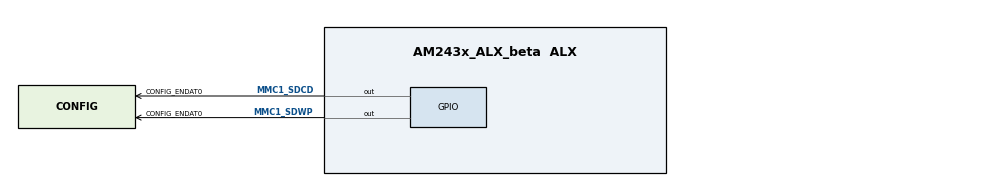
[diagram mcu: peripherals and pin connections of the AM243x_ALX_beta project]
/**
 * @cliArgs --device "AM243x_ALX_beta" --package "ALX" --part "ALX" --context "r5fss0-0" --product "MOTOR_CONTROL_SDK@09.01.00"
 * @versions {"tool":"1.18.0+3266"}
 */

/**
 * Import the modules used in this configuration.
 */
const debug_log  = scripting.addModule("/kernel/dpl/debug_log");
const mpu_armv7  = scripting.addModule("/kernel/dpl/mpu_armv7", {}, false);
const mpu_armv71 = mpu_armv7.addInstance();
const mpu_armv72 = mpu_armv7.addInstance();
const mpu_armv73 = mpu_armv7.addInstance();
const mpu_armv74 = mpu_armv7.addInstance();
const mpu_armv75 = mpu_armv7.addInstance();
const timer      = scripting.addModule("/kernel/dpl/timer", {}, false);
const timer1     = timer.addInstance();
const endat      = scripting.addModule("/position_sense/endat", {}, false);
const endat1     = endat.addInstance();

/**
 * Write custom configuration values to the imported modules.
 */
debug_log.enableUartLog        = true;
debug_log.enableCssLog         = false;
debug_log.uartLog.$name        = "CONFIG_UART_CONSOLE";
debug_log.uartLog.UART.$assign = "USART0";

const uart_v0_template  = scripting.addModule("/drivers/uart/v0/uart_v0_template", {}, false);
const uart_v0_template1 = uart_v0_template.addInstance({}, false);
uart_v0_template1.$name = "drivers_uart_v0_uart_v0_template0";
debug_log.uartLog.child = uart_v0_template1;

mpu_armv71.$name             = "CONFIG_MPU_REGION0";
mpu_armv71.size              = 31;
mpu_armv71.attributes        = "Device";
mpu_armv71.accessPermissions = "Supervisor RD+WR, User RD";
mpu_armv71.allowExecute      = false;

mpu_armv72.$name             = "CONFIG_MPU_REGION1";
mpu_armv72.size              = 15;
mpu_armv72.accessPermissions = "Supervisor RD+WR, User RD";

mpu_armv73.$name             = "CONFIG_MPU_REGION2";
mpu_armv73.baseAddr          = 0x41010000;
mpu_armv73.size              = 15;
mpu_armv73.accessPermissions = "Supervisor RD+WR, User RD";

mpu_armv74.$name             = "CONFIG_MPU_REGION3";
mpu_armv74.accessPermissions = "Supervisor RD+WR, User RD";
mpu_armv74.baseAddr          = 0x70000000;
mpu_armv74.size              = 21;

mpu_armv75.$name             = "CONFIG_MPU_REGION4";
mpu_armv75.baseAddr          = 0x60000000;
mpu_armv75.size              = 28;
mpu_armv75.accessPermissions = "Supervisor RD, User RD";

timer1.$name         = "CONFIG_TIMER0";
timer1.intrPriority  = 0;
timer1.timerCallback = "endat_position_loop";
timer1.TIMER.$assign = "DMTIMER0";

endat1.$name                        = "CONFIG_ENDAT0";
endat1.Booster_Pack                 = true;
endat1.Channel_2                    = true;
endat1.PRU_ICSSG0_PRU.$assign       = "PRU_ICSSG0_PRU1";
endat1.PRU_ICSSG0_PRU.GPO2.$assign  = "PRG0_PRU1_GPO2";
endat1.PRU_ICSSG0_PRU.GPO1.$assign  = "PRG0_PRU1_GPO1";
endat1.PRU_ICSSG0_PRU.GPO0.$assign  = "PRG0_PRU1_GPO0";
endat1.PRU_ICSSG0_PRU.GPI13.$assign = "PRG0_PRU1_GPO13";
endat1.PRU_ICSSG0_PRU.GPO8.$assign  = "PRG0_PRU1_GPO8";
endat1.PRU_ICSSG0_PRU.GPO12.$assign = "PRG0_PRU1_GPO12";
endat1.PRU_ICSSG0_PRU.GPO6.$assign  = "PRG0_PRU1_GPO6";
endat1.PRU_ICSSG0_PRU.GPI11.$assign = "PRG0_PRU1_GPO11";

endat1.ENC1_EN.GPIO.$assign         = "GPIO1";
endat1.ENC1_EN.$name                = "ENC1_EN";
endat1.ENC1_EN.GPIO.gpioPin.pu_pd   = "pu";
endat1.ENC1_EN.GPIO.gpioPin.rx      = false;
endat1.ENC1_EN.GPIO.gpioPin.$assign = "MMC1_SDWP";

endat1.ENC2_EN.$name                = "ENC2_EN";
endat1.ENC2_EN.GPIO.gpioPin.pu_pd   = "pu";
endat1.ENC2_EN.GPIO.gpioPin.rx      = false;
endat1.ENC2_EN.GPIO.$assign         = "GPIO1";
endat1.ENC2_EN.GPIO.gpioPin.$assign = "MMC1_SDCD";

const pruicss                            = scripting.addModule("/drivers/pruicss/pruicss", {}, false);
const pruicss1                           = pruicss.addInstance({}, false);
pruicss1.$name                           = "CONFIG_PRU_ICSS0";
endat1.pru                               = pruicss1;
pruicss1.AdditionalICSSSettings[0].$name = "CONFIG_PRU_ICSS_IO0";

/**
 * Pinmux solution for unlocked pins/peripherals. This ensures that minor changes to the automatic solver in a future
 * version of the tool will not impact the pinmux you originally saw.  These lines can be completely deleted in order to
 * re-solve from scratch.
 */
debug_log.uartLog.UART.RXD.$suggestSolution = "UART0_RXD";
debug_log.uartLog.UART.TXD.$suggestSolution = "UART0_TXD";
